# RA6M1 register map
Vendor: Renesas Electronics Corporation; Series: RA6; File version: 1.2
CPU: CM4 r0p1, little endian, MPU, FPU, VTOR, 4 interrupt priority bits
Registers are 8-bit, read-write, reset 0x0 unless marked. A register's access mark holds for its fields unless they carry their own. Offsets are from the block's base; [hi:lo] are bit positions; 'fields as' and 'values as' point back to an identical list.

## SPMON — CPU Stack Pointer Monitor
Base 0x40000D00
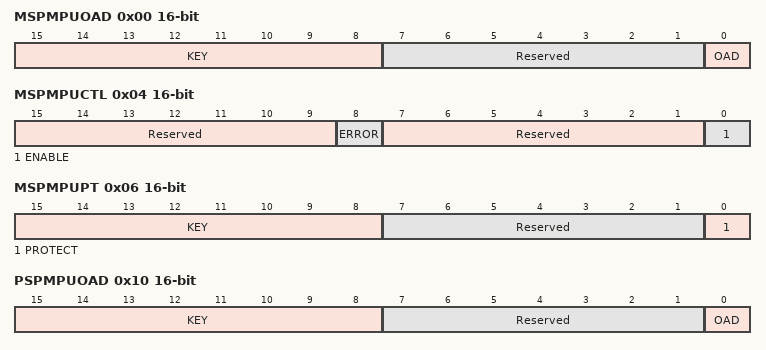
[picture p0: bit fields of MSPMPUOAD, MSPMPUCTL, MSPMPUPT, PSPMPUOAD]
0x00 MSPMPUOAD 16-bit — Stack Pointer Monitor Operation After Detection Register
  [15:8] KEY wo — Write Keyword The data written to these bits are not stored.
    165=Writing to the OAD bit is valid, when the KEY bits are written 0xA5; other=others (Writing to the OAD bit is invalid.)
  [7:1] Reserved — These bits are read as 0000000. The write value should be 0000000.
  [0] OAD — Operation after detection
    1=Reset; 0=Non-maskable interrupt
0x04 MSPMPUCTL 16-bit (reset mask 0xFEFF) — Stack Pointer Monitor Access Control Register
  [15:9] Reserved — These bits are read as 0000000. The write value should be 0000000.
  [8] ERROR — Stack Pointer Monitor Error Flag
    0=No stack pointer overflow or underflow occurred; 1=Stack pointer overflow or underflow occurred
  [7:1] Reserved — These bits are read as 0000000. The write value should be 0000000.
  [0] ENABLE — Stack Pointer Monitor Enable
    0=Disable stack pointer monitor; 1=Enable stack pointer monitor
0x06 MSPMPUPT 16-bit — Stack Pointer Monitor Protection Register
  [15:8] KEY wo — Key Code Write data is not saved.
    165=Writing to the PROTECT bit is valid, when the KEY bits are written 0xA5; other=others (Writing to the PROTECT bit is invalid.)
  [7:1] Reserved — These bits are read as 0000000. The write value should be 0000000.
  [0] PROTECT — Protection of register
    0=Stack pointer monitor register writes are permitted; 1=Stack pointer monitor register writes are protected. Reads are permitted.
0x08 MSPMPUSA 32-bit (reset mask 0x3) — Main Stack Pointer Monitor Start Address Register
  [31:0] MSPMPUSA range 0x1FF00000..0x200FFFFC — Region Start Address : Address where the region starts, for use in region determination. NOTE: Range: 0x1FF00000-0x200FFFFC The low-order 2 bits are fixed to 0.
0x0C MSPMPUEA 32-bit reset 0x3 (reset mask 0x3) — Main Stack Pointer Monitor End Address Register
  [31:0] MSPMPUEA range 0x1FF00003..0x200FFFFF — Region End Address : Address where the region ends, for use in region determination. NOTE: Range: 0x1FF00003-0x200FFFFF The low-order 2 bits are fixed to 1.
0x10 PSPMPUOAD 16-bit — Stack Pointer Monitor Operation After Detection Register
  fields as MSPMPUOAD
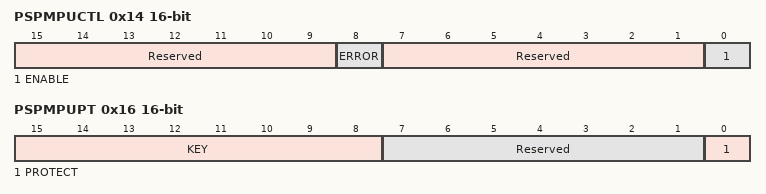
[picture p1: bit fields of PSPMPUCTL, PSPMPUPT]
0x14 PSPMPUCTL 16-bit (reset mask 0xFEFF) — Stack Pointer Monitor Access Control Register
  [15:9] Reserved — These bits are read as 0000000. The write value should be 0000000.
  [8] ERROR ro — Stack Pointer Monitor Error Flag
    values as MSPMPUCTL.ERROR
  [7:1] Reserved — These bits are read as 0000000. The write value should be 0000000.
  [0] ENABLE — Stack Pointer Monitor Enable
    values as MSPMPUCTL.ENABLE
0x16 PSPMPUPT 16-bit — Stack Pointer Monitor Protection Register
  fields as MSPMPUPT
0x18 PSPMPUSA 32-bit (reset mask 0x3) — Process Stack Pointer Monitor Start Address Register
  [31:0] PSPMPUSA range 0x1FF00000..0x200FFFFC — Region Start Address : Address where the region starts, for use in region determination. NOTE: Range: 0x1FF00000-0x200FFFFC The low-order 2 bits are fixed to 0.
0x1C PSPMPUEA 32-bit reset 0x3 (reset mask 0x3) — Process Stack Pointer Monitor End Address Register
  [31:0] PSPMPUEA range 0x1FF00003..0x200FFFFF — Region End Address : Address where the region ends, for use in region determination. NOTE: Range: 0x1FF00003-0x200FFFFF The low-order 2 bits are fixed to 1.

## TSD — Temperature Sensor Data
Base 0x407FB17C
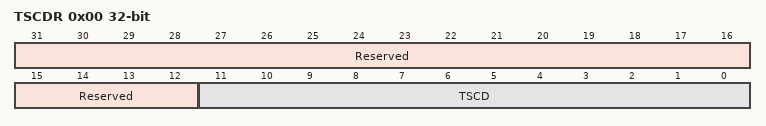
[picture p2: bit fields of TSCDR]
0x00 TSCDR 32-bit ro (reset mask 0xFFFFF000) — Temperature Sensor Calibration Data Register
  [31:12] Reserved — These bits are read as 00000000000000000000.
  [11:0] TSCD — Temperature sensor calibration data is a digital value obtained using the 12-bit A/D converter unit 0 to convert the voltage output by the temperature sensor under the condition Ta = Tj = 127°C and AVCC0 = 3.3 V.
